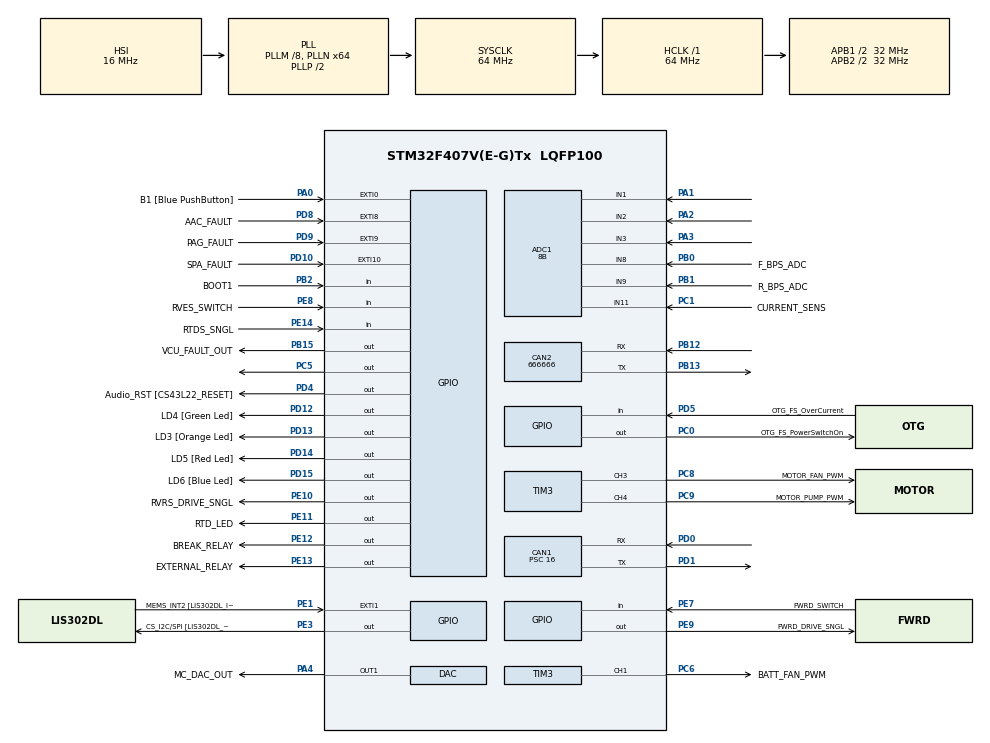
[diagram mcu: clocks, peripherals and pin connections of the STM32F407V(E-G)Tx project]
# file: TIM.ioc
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ADC1.Channel-3\#ChannelRegularConversion=ADC_CHANNEL_1
ADC1.Channel-5\#ChannelRegularConversion=ADC_CHANNEL_2
ADC1.ClockPrescaler=ADC_CLOCK_SYNC_PCLK_DIV2
ADC1.ContinuousConvMode=DISABLE
ADC1.DMAContinuousRequests=ENABLE
ADC1.EOCSelection=ADC_EOC_SEQ_CONV
ADC1.ExternalTrigConv=ADC_EXTERNALTRIGCONV_T2_TRGO
ADC1.NbrOfConversion=2
ADC1.NbrOfConversionFlag=1
ADC1.Rank-3\#ChannelRegularConversion=1
ADC1.Rank-5\#ChannelRegularConversion=2
ADC1.Resolution=ADC_RESOLUTION_8B
ADC1.SamplingTime-3\#ChannelRegularConversion=ADC_SAMPLETIME_3CYCLES
ADC1.SamplingTime-5\#ChannelRegularConversion=ADC_SAMPLETIME_3CYCLES
ADC1.master=1
CAN1.BS1=CAN_BS1_2TQ
CAN1.CalculateBaudRate=500000
CAN1.CalculateTimeBit=2000
CAN1.CalculateTimeQuantum=500.0
CAN1.Prescaler=16
CAN2.CalculateBaudRate=666666
CAN2.CalculateTimeBit=1500
CAN2.CalculateTimeQuantum=500.0
Dma.ADC1.0.Direction=DMA_PERIPH_TO_MEMORY
Dma.ADC1.0.FIFOMode=DMA_FIFOMODE_DISABLE
Dma.ADC1.0.Instance=DMA2_Stream0
Dma.ADC1.0.MemDataAlignment=DMA_MDATAALIGN_HALFWORD
Dma.ADC1.0.MemInc=DMA_MINC_ENABLE
Dma.ADC1.0.Mode=DMA_CIRCULAR
Dma.ADC1.0.PeriphDataAlignment=DMA_PDATAALIGN_HALFWORD
Dma.ADC1.0.PeriphInc=DMA_PINC_DISABLE
Dma.ADC1.0.Priority=DMA_PRIORITY_LOW
Dma.Request0=ADC1
Mcu.Family=STM32F4
Mcu.Name=STM32F407V(E-G)Tx
Mcu.Package=LQFP100
NVIC.ADC_IRQn=true\:0\:0\:false\:false\:true\:true\:true\:true
NVIC.DMA2_Stream0_IRQn=true\:0\:0\:false\:false\:true\:false\:true\:true
NVIC.EXTI0_IRQn=true\:0\:0\:false\:false\:true\:true\:true\:true
NVIC.EXTI15_10_IRQn=true\:0\:0\:false\:false\:true\:true\:true\:true
NVIC.EXTI9_5_IRQn=true\:0\:0\:false\:false\:true\:true\:true\:true
NVIC.PriorityGroup=NVIC_PRIORITYGROUP_0
PA0-WKUP.GPIO_Label=B1 [Blue PushButton]
PA0-WKUP.GPIO_ModeDefaultEXTI=GPIO_MODE_IT_RISING
PA0-WKUP.GPIO_PuPd=GPIO_NOPULL
PA0-WKUP.Signal=GPXTI0
PA1.Signal=ADCx_IN1
PA10.GPIO_Label=OTG_FS_ID
PA10.GPIO_Mode=GPIO_MODE_AF_PP
PA10.GPIO_PuPd=GPIO_NOPULL
PA10.GPIO_Speed=GPIO_SPEED_FREQ_LOW
PA10.Signal=USB_OTG_FS_ID
PA11.GPIO_Label=OTG_FS_DM
PA11.GPIO_Mode=GPIO_MODE_AF_PP
PA11.GPIO_PuPd=GPIO_NOPULL
PA11.GPIO_Speed=GPIO_SPEED_FREQ_LOW
PA11.Signal=USB_OTG_FS_DM
PA12.GPIO_Label=OTG_FS_DP
PA12.GPIO_Mode=GPIO_MODE_AF_PP
PA12.GPIO_PuPd=GPIO_NOPULL
PA12.GPIO_Speed=GPIO_SPEED_FREQ_LOW
PA12.Signal=USB_OTG_FS_DP
PA13.GPIO_Label=SWDIO
PA13.Signal=SYS_JTMS-SWDIO
PA14.GPIO_Label=SWCLK
PA14.Signal=SYS_JTCK-SWCLK
PA2.Signal=ADCx_IN2
PA3.Signal=ADCx_IN3
PA4.GPIO_Label=MC_DAC_OUT
PA4.Signal=COMP_DAC1_group
PA5.GPIO_Label=SPI1_SCK [LIS302DL_SCL/SPC]
PA5.GPIO_Mode=GPIO_MODE_AF_PP
PA5.GPIO_PuPd=GPIO_NOPULL
PA5.GPIO_Speed=GPIO_SPEED_FREQ_LOW
PA5.Signal=SPI1_SCK
PA6.GPIO_Label=SPI1_MISO [LIS302DL_SDO]
PA6.GPIO_Mode=GPIO_MODE_AF_PP
PA6.GPIO_PuPd=GPIO_NOPULL
PA6.GPIO_Speed=GPIO_SPEED_FREQ_LOW
PA6.Signal=SPI1_MISO
PA7.GPIO_Label=SPI1_MOSI [LIS302DL_SDA/SDI/SDO]
PA7.GPIO_Mode=GPIO_MODE_AF_PP
PA7.GPIO_PuPd=GPIO_NOPULL
PA7.GPIO_Speed=GPIO_SPEED_FREQ_LOW
PA7.Signal=SPI1_MOSI
PA9.GPIO_Label=VBUS_FS
PA9.GPIO_Mode=GPIO_MODE_INPUT
PA9.GPIO_PuPd=GPIO_NOPULL
PA9.Signal=USB_OTG_FS_VBUS
PB0.GPIO_Label=F_BPS_ADC
PB0.Signal=ADCx_IN8
PB1.GPIO_Label=R_BPS_ADC
PB1.Signal=ADCx_IN9
PB10.GPIO_Label=CLK_IN [MP45DT02_CLK]
PB10.GPIO_Mode=GPIO_MODE_AF_PP
PB10.GPIO_PuPd=GPIO_NOPULL
PB10.GPIO_Speed=GPIO_SPEED_FREQ_LOW
PB10.Signal=I2S2_CK
PB12.Mode=CAN_Activate
PB12.Signal=CAN2_RX
PB13.Mode=CAN_Activate
PB13.Signal=CAN2_TX
PB15.GPIO_Label=VCU_FAULT_OUT
PB15.Signal=GPIO_Output
PB2.GPIO_Label=BOOT1
PB2.GPIO_Mode=GPIO_MODE_INPUT
PB2.GPIO_PuPd=GPIO_NOPULL
PB2.Signal=GPIO_Input
PB3.GPIO_Label=SWO
PB3.Signal=SYS_JTDO-SWO
PB6.GPIO_Label=Audio_SCL [CS43L22_SCL]
PB6.GPIO_Mode=GPIO_MODE_AF_OD
PB6.GPIO_Pu=GPIO_PULLUP
PB6.GPIO_PuPd=GPIO_NOPULL
PB6.GPIO_Speed=GPIO_SPEED_FREQ_LOW
PB6.Signal=I2C1_SCL
PB9.GPIO_Label=Audio_SDA [CS43L22_SDA]
PB9.GPIO_Mode=GPIO_MODE_AF_OD
PB9.GPIO_Pu=GPIO_PULLUP
PB9.GPIO_PuPd=GPIO_NOPULL
PB9.GPIO_Speed=GPIO_SPEED_FREQ_LOW
PB9.Signal=I2C1_SDA
PC0.GPIO_Label=OTG_FS_PowerSwitchOn
PC0.GPIO_PuPd=GPIO_NOPULL
PC0.GPIO_Speed=GPIO_SPEED_FREQ_LOW
PC0.PinState=GPIO_PIN_SET
PC0.Signal=GPIO_Output
PC1.GPIO_Label=CURRENT_SENS
PC1.Signal=ADCx_IN11
PC10.GPIO_Label=I2S3_SCK [CS43L22_SCLK]
PC10.GPIO_Mode=GPIO_MODE_AF_PP
PC10.GPIO_PuPd=GPIO_NOPULL
PC10.GPIO_Speed=GPIO_SPEED_FREQ_LOW
PC10.Signal=I2S3_CK
PC12.GPIO_Label=I2S3_SD [CS43L22_SDIN]
PC12.GPIO_Mode=GPIO_MODE_AF_PP
PC12.GPIO_PuPd=GPIO_NOPULL
PC12.GPIO_Speed=GPIO_SPEED_FREQ_LOW
PC12.Signal=I2S3_SD
PC14-OSC32_IN.GPIO_Label=PC14-OSC32_IN
PC14-OSC32_IN.Signal=RCC_OSC32_IN
PC15-OSC32_OUT.GPIO_Label=PC15-OSC32_OUT
PC15-OSC32_OUT.Signal=RCC_OSC32_OUT
PC3.GPIO_Label=PDM_OUT [MP45DT02_DOUT]
PC3.GPIO_Mode=GPIO_MODE_AF_PP
PC3.GPIO_PuPd=GPIO_NOPULL
PC3.GPIO_Speed=GPIO_SPEED_FREQ_LOW
PC3.Signal=I2S2_SD
PC5.Signal=GPIO_Output
PC6.GPIO_Label=BATT_FAN_PWM
PC6.Signal=S_TIM3_CH1
PC7.GPIO_Label=I2S3_MCK [CS43L22_MCLK]
PC7.GPIO_Mode=GPIO_MODE_AF_PP
PC7.GPIO_PuPd=GPIO_NOPULL
PC7.GPIO_Speed=GPIO_SPEED_FREQ_LOW
PC7.Signal=I2S3_MCK
PC8.GPIO_Label=MOTOR_FAN_PWM
PC8.Signal=S_TIM3_CH3
PC9.GPIO_Label=MOTOR_PUMP_PWM
PC9.Signal=S_TIM3_CH4
PD0.Mode=CAN_Activate
PD0.Signal=CAN1_RX
PD1.Mode=CAN_Activate
PD1.Signal=CAN1_TX
PD10.GPIO_Label=SPA_FAULT
PD10.GPIO_PuPd=GPIO_NOPULL
PD10.Signal=GPXTI10
PD12.GPIO_Label=LD4 [Green Led]
PD12.GPIO_PuPd=GPIO_NOPULL
PD12.GPIO_Speed=GPIO_SPEED_FREQ_LOW
PD12.Signal=GPIO_Output
PD13.GPIO_Label=LD3 [Orange Led]
PD13.GPIO_PuPd=GPIO_NOPULL
PD13.GPIO_Speed=GPIO_SPEED_FREQ_LOW
PD13.Signal=GPIO_Output
PD14.GPIO_Label=LD5 [Red Led]
PD14.GPIO_PuPd=GPIO_NOPULL
PD14.GPIO_Speed=GPIO_SPEED_FREQ_LOW
PD14.Signal=GPIO_Output
PD15.GPIO_Label=LD6 [Blue Led]
PD15.GPIO_PuPd=GPIO_NOPULL
PD15.GPIO_Speed=GPIO_SPEED_FREQ_LOW
PD15.Signal=GPIO_Output
PD4.GPIO_Label=Audio_RST [CS43L22_RESET]
PD4.GPIO_PuPd=GPIO_NOPULL
PD4.GPIO_Speed=GPIO_SPEED_FREQ_LOW
PD4.Signal=GPIO_Output
PD5.GPIO_Label=OTG_FS_OverCurrent
PD5.GPIO_Mode=GPIO_MODE_INPUT
PD5.GPIO_PuPd=GPIO_NOPULL
PD5.Signal=GPIO_Input
PD8.GPIO_Label=AAC_FAULT
PD8.GPIO_PuPd=GPIO_NOPULL
PD8.Signal=GPXTI8
PD9.GPIO_Label=PAG_FAULT
PD9.GPIO_PuPd=GPIO_NOPULL
PD9.Signal=GPXTI9
PE1.GPIO_Label=MEMS_INT2 [LIS302DL_INT2]
PE1.GPIO_ModeDefaultEXTI=GPIO_MODE_EVT_RISING
PE1.GPIO_PuPd=GPIO_NOPULL
PE1.Signal=GPXTI1
PE10.GPIO_Label=RVRS_DRIVE_SNGL
PE10.Signal=GPIO_Output
PE11.GPIO_Label=RTD_LED
PE11.Signal=GPIO_Output
PE12.GPIO_Label=BREAK_RELAY
PE12.Signal=GPIO_Output
PE13.GPIO_Label=EXTERNAL_RELAY
PE13.Signal=GPIO_Output
PE14.GPIO_Label=RTDS_SNGL
PE14.GPIO_PuPd=GPIO_PULLDOWN
PE14.Signal=GPIO_Input
PE3.GPIO_Label=CS_I2C/SPI [LIS302DL_CS_I2C/SPI]
PE3.GPIO_PuPd=GPIO_NOPULL
PE3.GPIO_Speed=GPIO_SPEED_FREQ_LOW
PE3.Signal=GPIO_Output
PE7.GPIO_Label=FWRD_SWITCH
PE7.Signal=GPIO_Input
PE8.GPIO_Label=RVES_SWITCH
PE8.Signal=GPIO_Input
PE9.GPIO_Label=FWRD_DRIVE_SNGL
PE9.GPIO_ModeDefaultOutputPP=GPIO_MODE_OUTPUT_PP
PE9.GPIO_PuPd=GPIO_NOPULL
PE9.Signal=GPIO_Output
PH0-OSC_IN.GPIO_Label=PH0-OSC_IN
PH0-OSC_IN.Signal=RCC_OSC_IN
PH1-OSC_OUT.GPIO_Label=PH1-OSC_OUT
PH1-OSC_OUT.Signal=RCC_OSC_OUT
ProjectManager.HeapSize=0x200
ProjectManager.StackSize=0x400
ProjectManager.TargetToolchain=STM32CubeIDE
RCC.48MHZClocksFreq_Value=18285714.285714287
RCC.AHBFreq_Value=64000000
RCC.APB1CLKDivider=RCC_HCLK_DIV2
RCC.APB1Freq_Value=32000000
RCC.APB1TimFreq_Value=64000000
RCC.APB2CLKDivider=RCC_HCLK_DIV2
RCC.APB2Freq_Value=32000000
RCC.APB2TimFreq_Value=64000000
RCC.CortexFreq_Value=64000000
RCC.HCLKFreq_Value=64000000
RCC.HSE_VALUE=8000000
RCC.HSI_VALUE=16000000
RCC.LSE_VALUE=32768
RCC.PLLM=8
RCC.PLLN=64
RCC.PLLQ=7
RCC.SYSCLKFreq_VALUE=64000000
RCC.SYSCLKSource=RCC_SYSCLKSOURCE_PLLCLK
RCC.VCOOutputFreq_Value=128000000
SH.ADCx_IN1.0=ADC1_IN1,IN1
SH.ADCx_IN11.0=ADC1_IN11,IN11
SH.ADCx_IN2.0=ADC1_IN2,IN2
SH.ADCx_IN3.0=ADC1_IN3,IN3
SH.ADCx_IN8.0=ADC1_IN8,IN8
SH.ADCx_IN9.0=ADC1_IN9,IN9
SH.COMP_DAC1_group.0=DAC_OUT1,DAC_OUT1
SH.S_TIM3_CH1.0=TIM3_CH1,PWM Generation1 CH1
SH.S_TIM3_CH3.0=TIM3_CH3,PWM Generation3 CH3
SH.S_TIM3_CH4.0=TIM3_CH4,PWM Generation4 CH4
TIM1.Period=0xffff-1
TIM1.Prescaler=64-1
TIM2.Channel-PWM\ Generation1\ No\ Output=TIM_CHANNEL_1
TIM2.Period=65536-1
TIM2.TIM_MasterOutputTrigger=TIM_TRGO_UPDATE
TIM3.Channel-PWM\ Generation1\ CH1=TIM_CHANNEL_1
TIM3.Channel-PWM\ Generation3\ CH3=TIM_CHANNEL_3
TIM3.Channel-PWM\ Generation4\ CH4=TIM_CHANNEL_4
VP_TIM1_VS_ClockSourceINT.Mode=Internal
VP_TIM2_VS_no_output1.Mode=PWM Generation1 No Output
VP_TIM6_VS_ClockSourceINT.Mode=Enable_Timer
VP_TIM8_VS_ClockSourceINT.Mode=Internal
board=STM32F407G-DISC1

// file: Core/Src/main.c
/* USER CODE BEGIN Header */
/**
  ******************************************************************************
  * @file           : main.c
  * @brief          : Main program body
  ******************************************************************************
  * @attention
  *
  * Copyright (c) 2023 STMicroelectronics.
  * All rights reserved.
  *
  * This software is licensed under terms that can be found in the LICENSE file
  * in the root directory of this software component.
  * If no LICENSE file comes with this software, it is provided AS-IS.
  *
  ******************************************************************************
  */
/* USER CODE END Header */
#include "main.h"

/* USER CODE BEGIN Includes */
#include "TIM.h"
#include "DRIVER_IO.h"
#include "app_main.h"
/* USER CODE END Includes */

ADC_HandleTypeDef hadc1;
DMA_HandleTypeDef hdma_adc1;

CAN_HandleTypeDef hcan1;
CAN_HandleTypeDef hcan2;

DAC_HandleTypeDef hdac;

TIM_HandleTypeDef htim1;
TIM_HandleTypeDef htim2;
TIM_HandleTypeDef htim3;
TIM_HandleTypeDef htim6;
TIM_HandleTypeDef htim8;

void SystemClock_Config(void);
static void MX_GPIO_Init(void);
static void MX_DMA_Init(void);
static void MX_TIM1_Init(void);
static void MX_CAN1_Init(void);
static void MX_ADC1_Init(void);
static void MX_DAC_Init(void);
static void MX_TIM6_Init(void);
static void MX_TIM2_Init(void);
static void MX_TIM8_Init(void);
static void MX_CAN2_Init(void);
static void MX_TIM3_Init(void);

int main(void)
{

  /* MCU Configuration--------------------------------------------------------*/

  /* Reset of all peripherals, Initializes the Flash interface and the Systick. */
  HAL_Init();

  /* Configure the system clock */
  SystemClock_Config();

  /* Initialize all configured peripherals */
  MX_GPIO_Init();
  MX_DMA_Init();
  MX_TIM1_Init();
  MX_CAN1_Init();
  MX_ADC1_Init();
  MX_DAC_Init();
  MX_TIM6_Init();
  MX_TIM2_Init();
  MX_TIM8_Init();
  MX_CAN2_Init();
  MX_TIM3_Init();
  /* USER CODE BEGIN 2 */
  AppConfig();
  AppMain();
  /* USER CODE END 2 */

  /* Infinite loop */
  /* USER CODE BEGIN WHILE */
  while (1)		// We don't use this, instead we use the loop inside AppMain()
  {
    /* USER CODE END WHILE */

  }
}

void SystemClock_Config(void)
{
  RCC_OscInitTypeDef RCC_OscInitStruct = {0};
  RCC_ClkInitTypeDef RCC_ClkInitStruct = {0};

  /** Configure the main internal regulator output voltage
  */
  __HAL_RCC_PWR_CLK_ENABLE();
  __HAL_PWR_VOLTAGESCALING_CONFIG(PWR_REGULATOR_VOLTAGE_SCALE1);

  /** Initializes the RCC Oscillators according to the specified parameters
  * in the RCC_OscInitTypeDef structure.
  */
  RCC_OscInitStruct.OscillatorType = RCC_OSCILLATORTYPE_HSI;
  RCC_OscInitStruct.HSIState = RCC_HSI_ON;
  RCC_OscInitStruct.HSICalibrationValue = RCC_HSICALIBRATION_DEFAULT;
  RCC_OscInitStruct.PLL.PLLState = RCC_PLL_ON;
  RCC_OscInitStruct.PLL.PLLSource = RCC_PLLSOURCE_HSI;
  RCC_OscInitStruct.PLL.PLLM = 8;
  RCC_OscInitStruct.PLL.PLLN = 64;
  RCC_OscInitStruct.PLL.PLLP = RCC_PLLP_DIV2;
  RCC_OscInitStruct.PLL.PLLQ = 7;
  if (HAL_RCC_OscConfig(&RCC_OscInitStruct) != HAL_OK)
  {
    Error_Handler();
  }

  /** Initializes the CPU, AHB and APB buses clocks
  */
  RCC_ClkInitStruct.ClockType = RCC_CLOCKTYPE_HCLK|RCC_CLOCKTYPE_SYSCLK
                              |RCC_CLOCKTYPE_PCLK1|RCC_CLOCKTYPE_PCLK2;
  RCC_ClkInitStruct.SYSCLKSource = RCC_SYSCLKSOURCE_PLLCLK;
  RCC_ClkInitStruct.AHBCLKDivider = RCC_SYSCLK_DIV1;
  RCC_ClkInitStruct.APB1CLKDivider = RCC_HCLK_DIV2;
  RCC_ClkInitStruct.APB2CLKDivider = RCC_HCLK_DIV2;

  if (HAL_RCC_ClockConfig(&RCC_ClkInitStruct, FLASH_LATENCY_2) != HAL_OK)
  {
    Error_Handler();
  }
}

static void MX_ADC1_Init(void)
{

  ADC_ChannelConfTypeDef sConfig = {0};

  /** Configure the global features of the ADC (Clock, Resolution, Data Alignment and number of conversion)
  */
  hadc1.Instance = ADC1;
  hadc1.Init.ClockPrescaler = ADC_CLOCK_SYNC_PCLK_DIV2;
  hadc1.Init.Resolution = ADC_RESOLUTION_8B;
  hadc1.Init.ScanConvMode = ENABLE;
  hadc1.Init.ContinuousConvMode = DISABLE;
  hadc1.Init.DiscontinuousConvMode = DISABLE;
  hadc1.Init.ExternalTrigConvEdge = ADC_EXTERNALTRIGCONVEDGE_RISING;
  hadc1.Init.ExternalTrigConv = ADC_EXTERNALTRIGCONV_T2_TRGO;
  hadc1.Init.DataAlign = ADC_DATAALIGN_RIGHT;
  hadc1.Init.NbrOfConversion = 2;
  hadc1.Init.DMAContinuousRequests = ENABLE;
  hadc1.Init.EOCSelection = ADC_EOC_SEQ_CONV;
  if (HAL_ADC_Init(&hadc1) != HAL_OK)
  {
    Error_Handler();
  }

  /** Configure for the selected ADC regular channel its corresponding rank in the sequencer and its sample time.
  */
  sConfig.Channel = ADC_CHANNEL_1;
  sConfig.Rank = 1;
  sConfig.SamplingTime = ADC_SAMPLETIME_3CYCLES;
  if (HAL_ADC_ConfigChannel(&hadc1, &sConfig) != HAL_OK)
  {
    Error_Handler();
  }

  /** Configure for the selected ADC regular channel its corresponding rank in the sequencer and its sample time.
  */
  sConfig.Channel = ADC_CHANNEL_2;
  sConfig.Rank = 2;
  if (HAL_ADC_ConfigChannel(&hadc1, &sConfig) != HAL_OK)
  {
    Error_Handler();
  }

}

static void MX_CAN1_Init(void)
{

  hcan1.Instance = CAN1;
  hcan1.Init.Prescaler = 16;
  hcan1.Init.Mode = CAN_MODE_NORMAL;
  hcan1.Init.SyncJumpWidth = CAN_SJW_1TQ;
  hcan1.Init.TimeSeg1 = CAN_BS1_2TQ;
  hcan1.Init.TimeSeg2 = CAN_BS2_1TQ;
  hcan1.Init.TimeTriggeredMode = DISABLE;
  hcan1.Init.AutoBusOff = DISABLE;
  hcan1.Init.AutoWakeUp = DISABLE;
  hcan1.Init.AutoRetransmission = DISABLE;
  hcan1.Init.ReceiveFifoLocked = DISABLE;
  hcan1.Init.TransmitFifoPriority = DISABLE;
  if (HAL_CAN_Init(&hcan1) != HAL_OK)
  {
    Error_Handler();
  }

}

static void MX_CAN2_Init(void)
{

  hcan2.Instance = CAN2;
  hcan2.Init.Prescaler = 16;
  hcan2.Init.Mode = CAN_MODE_NORMAL;
  hcan2.Init.SyncJumpWidth = CAN_SJW_1TQ;
  hcan2.Init.TimeSeg1 = CAN_BS1_1TQ;
  hcan2.Init.TimeSeg2 = CAN_BS2_1TQ;
  hcan2.Init.TimeTriggeredMode = DISABLE;
  hcan2.Init.AutoBusOff = DISABLE;
  hcan2.Init.AutoWakeUp = DISABLE;
  hcan2.Init.AutoRetransmission = DISABLE;
  hcan2.Init.ReceiveFifoLocked = DISABLE;
  hcan2.Init.TransmitFifoPriority = DISABLE;
  if (HAL_CAN_Init(&hcan2) != HAL_OK)
  {
    Error_Handler();
  }

}

static void MX_DAC_Init(void)
{

  DAC_ChannelConfTypeDef sConfig = {0};

  /** DAC Initialization
  */
  hdac.Instance = DAC;
  if (HAL_DAC_Init(&hdac) != HAL_OK)
  {
    Error_Handler();
  }

  /** DAC channel OUT1 config
  */
  sConfig.DAC_Trigger = DAC_TRIGGER_NONE;
  sConfig.DAC_OutputBuffer = DAC_OUTPUTBUFFER_ENABLE;
  if (HAL_DAC_ConfigChannel(&hdac, &sConfig, DAC_CHANNEL_1) != HAL_OK)
  {
    Error_Handler();
  }

}

static void MX_TIM1_Init(void)
{

  TIM_ClockConfigTypeDef sClockSourceConfig = {0};
  TIM_MasterConfigTypeDef sMasterConfig = {0};

  htim1.Instance = TIM1;
  htim1.Init.Prescaler = 64-1;
  htim1.Init.CounterMode = TIM_COUNTERMODE_UP;
  htim1.Init.Period = 0xffff-1;
  htim1.Init.ClockDivision = TIM_CLOCKDIVISION_DIV1;
  htim1.Init.RepetitionCounter = 0;
  htim1.Init.AutoReloadPreload = TIM_AUTORELOAD_PRELOAD_DISABLE;
  if (HAL_TIM_Base_Init(&htim1) != HAL_OK)
  {
    Error_Handler();
  }
  sClockSourceConfig.ClockSource = TIM_CLOCKSOURCE_INTERNAL;
  if (HAL_TIM_ConfigClockSource(&htim1, &sClockSourceConfig) != HAL_OK)
  {
    Error_Handler();
  }
  sMasterConfig.MasterOutputTrigger = TIM_TRGO_RESET;
  sMasterConfig.MasterSlaveMode = TIM_MASTERSLAVEMODE_DISABLE;
  if (HAL_TIMEx_MasterConfigSynchronization(&htim1, &sMasterConfig) != HAL_OK)
  {
    Error_Handler();
  }

}

static void MX_TIM2_Init(void)
{

  TIM_MasterConfigTypeDef sMasterConfig = {0};
  TIM_OC_InitTypeDef sConfigOC = {0};

  htim2.Instance = TIM2;
  htim2.Init.Prescaler = 0;
  htim2.Init.CounterMode = TIM_COUNTERMODE_UP;
  htim2.Init.Period = 65536-1;
  htim2.Init.ClockDivision = TIM_CLOCKDIVISION_DIV1;
  htim2.Init.AutoReloadPreload = TIM_AUTORELOAD_PRELOAD_DISABLE;
  if (HAL_TIM_PWM_Init(&htim2) != HAL_OK)
  {
    Error_Handler();
  }
  sMasterConfig.MasterOutputTrigger = TIM_TRGO_UPDATE;
  sMasterConfig.MasterSlaveMode = TIM_MASTERSLAVEMODE_DISABLE;
  if (HAL_TIMEx_MasterConfigSynchronization(&htim2, &sMasterConfig) != HAL_OK)
  {
    Error_Handler();
  }
  sConfigOC.OCMode = TIM_OCMODE_PWM1;
  sConfigOC.Pulse = 0;
  sConfigOC.OCPolarity = TIM_OCPOLARITY_HIGH;
  sConfigOC.OCFastMode = TIM_OCFAST_DISABLE;
  if (HAL_TIM_PWM_ConfigChannel(&htim2, &sConfigOC, TIM_CHANNEL_1) != HAL_OK)
  {
    Error_Handler();
  }

}

static void MX_TIM3_Init(void)
{

  TIM_MasterConfigTypeDef sMasterConfig = {0};
  TIM_OC_InitTypeDef sConfigOC = {0};

  htim3.Instance = TIM3;
  htim3.Init.Prescaler = 0;
  htim3.Init.CounterMode = TIM_COUNTERMODE_UP;
  htim3.Init.Period = 65535;
  htim3.Init.ClockDivision = TIM_CLOCKDIVISION_DIV1;
  htim3.Init.AutoReloadPreload = TIM_AUTORELOAD_PRELOAD_DISABLE;
  if (HAL_TIM_PWM_Init(&htim3) != HAL_OK)
  {
    Error_Handler();
  }
  sMasterConfig.MasterOutputTrigger = TIM_TRGO_RESET;
  sMasterConfig.MasterSlaveMode = TIM_MASTERSLAVEMODE_DISABLE;
  if (HAL_TIMEx_MasterConfigSynchronization(&htim3, &sMasterConfig) != HAL_OK)
  {
    Error_Handler();
  }
  sConfigOC.OCMode = TIM_OCMODE_PWM1;
  sConfigOC.Pulse = 0;
  sConfigOC.OCPolarity = TIM_OCPOLARITY_HIGH;
  sConfigOC.OCFastMode = TIM_OCFAST_DISABLE;
  if (HAL_TIM_PWM_ConfigChannel(&htim3, &sConfigOC, TIM_CHANNEL_1) != HAL_OK)
  {
    Error_Handler();
  }
  if (HAL_TIM_PWM_ConfigChannel(&htim3, &sConfigOC, TIM_CHANNEL_3) != HAL_OK)
  {
    Error_Handler();
  }
  if (HAL_TIM_PWM_ConfigChannel(&htim3, &sConfigOC, TIM_CHANNEL_4) != HAL_OK)
  {
    Error_Handler();
  }
  HAL_TIM_MspPostInit(&htim3);

}

static void MX_TIM6_Init(void)
{

  TIM_MasterConfigTypeDef sMasterConfig = {0};

  htim6.Instance = TIM6;
  htim6.Init.Prescaler = 0;
  htim6.Init.CounterMode = TIM_COUNTERMODE_UP;
  htim6.Init.Period = 65535;
  htim6.Init.AutoReloadPreload = TIM_AUTORELOAD_PRELOAD_DISABLE;
  if (HAL_TIM_Base_Init(&htim6) != HAL_OK)
  {
    Error_Handler();
  }
  sMasterConfig.MasterOutputTrigger = TIM_TRGO_RESET;
  sMasterConfig.MasterSlaveMode = TIM_MASTERSLAVEMODE_DISABLE;
  if (HAL_TIMEx_MasterConfigSynchronization(&htim6, &sMasterConfig) != HAL_OK)
  {
    Error_Handler();
  }

}

static void MX_TIM8_Init(void)
{

  TIM_ClockConfigTypeDef sClockSourceConfig = {0};
  TIM_MasterConfigTypeDef sMasterConfig = {0};

  htim8.Instance = TIM8;
  htim8.Init.Prescaler = 0;
  htim8.Init.CounterMode = TIM_COUNTERMODE_UP;
  htim8.Init.Period = 65535;
  htim8.Init.ClockDivision = TIM_CLOCKDIVISION_DIV1;
  htim8.Init.RepetitionCounter = 0;
  htim8.Init.AutoReloadPreload = TIM_AUTORELOAD_PRELOAD_DISABLE;
  if (HAL_TIM_Base_Init(&htim8) != HAL_OK)
  {
    Error_Handler();
  }
  sClockSourceConfig.ClockSource = TIM_CLOCKSOURCE_INTERNAL;
  if (HAL_TIM_ConfigClockSource(&htim8, &sClockSourceConfig) != HAL_OK)
  {
    Error_Handler();
  }
  sMasterConfig.MasterOutputTrigger = TIM_TRGO_RESET;
  sMasterConfig.MasterSlaveMode = TIM_MASTERSLAVEMODE_DISABLE;
  if (HAL_TIMEx_MasterConfigSynchronization(&htim8, &sMasterConfig) != HAL_OK)
  {
    Error_Handler();
  }

}

static void MX_DMA_Init(void)
{

  /* DMA controller clock enable */
  __HAL_RCC_DMA2_CLK_ENABLE();

  /* DMA interrupt init */
  /* DMA2_Stream0_IRQn interrupt configuration */
  HAL_NVIC_SetPriority(DMA2_Stream0_IRQn, 0, 0);
  HAL_NVIC_EnableIRQ(DMA2_Stream0_IRQn);

}

static void MX_GPIO_Init(void)
{
  GPIO_InitTypeDef GPIO_InitStruct = {0};

  /* GPIO Ports Clock Enable */
  __HAL_RCC_GPIOE_CLK_ENABLE();
  __HAL_RCC_GPIOC_CLK_ENABLE();
  __HAL_RCC_GPIOH_CLK_ENABLE();
  __HAL_RCC_GPIOA_CLK_ENABLE();
  __HAL_RCC_GPIOB_CLK_ENABLE();
  __HAL_RCC_GPIOD_CLK_ENABLE();

  /*Configure GPIO pin Output Level */
  HAL_GPIO_WritePin(GPIOE, CS_I2C_SPI_Pin|FWRD_DRIVE_SNGL_Pin|RVRS_DRIVE_SNGL_Pin|RTD_LED_Pin
                          |BREAK_RELAY_Pin|EXTERNAL_RELAY_Pin, GPIO_PIN_RESET);

  /*Configure GPIO pin Output Level */
  HAL_GPIO_WritePin(OTG_FS_PowerSwitchOn_GPIO_Port, OTG_FS_PowerSwitchOn_Pin, GPIO_PIN_SET);

  /*Configure GPIO pin Output Level */
  HAL_GPIO_WritePin(GPIOC, GPIO_PIN_5, GPIO_PIN_RESET);

  /*Configure GPIO pin Output Level */
  HAL_GPIO_WritePin(VCU_FAULT_OUT_GPIO_Port, VCU_FAULT_OUT_Pin, GPIO_PIN_RESET);

  /*Configure GPIO pin Output Level */
  HAL_GPIO_WritePin(GPIOD, LD4_Pin|LD3_Pin|LD5_Pin|LD6_Pin
                          |Audio_RST_Pin, GPIO_PIN_RESET);

  /*Configure GPIO pins : CS_I2C_SPI_Pin FWRD_DRIVE_SNGL_Pin RVRS_DRIVE_SNGL_Pin RTD_LED_Pin
                           BREAK_RELAY_Pin EXTERNAL_RELAY_Pin */
  GPIO_InitStruct.Pin = CS_I2C_SPI_Pin|FWRD_DRIVE_SNGL_Pin|RVRS_DRIVE_SNGL_Pin|RTD_LED_Pin
                          |BREAK_RELAY_Pin|EXTERNAL_RELAY_Pin;
  GPIO_InitStruct.Mode = GPIO_MODE_OUTPUT_PP;
  GPIO_InitStruct.Pull = GPIO_NOPULL;
  GPIO_InitStruct.Speed = GPIO_SPEED_FREQ_LOW;
  HAL_GPIO_Init(GPIOE, &GPIO_InitStruct);

  /*Configure GPIO pins : OTG_FS_PowerSwitchOn_Pin PC5 */
  GPIO_InitStruct.Pin = OTG_FS_PowerSwitchOn_Pin|GPIO_PIN_5;
  GPIO_InitStruct.Mode = GPIO_MODE_OUTPUT_PP;
  GPIO_InitStruct.Pull = GPIO_NOPULL;
  GPIO_InitStruct.Speed = GPIO_SPEED_FREQ_LOW;
  HAL_GPIO_Init(GPIOC, &GPIO_InitStruct);

  /*Configure GPIO pin : PDM_OUT_Pin */
  GPIO_InitStruct.Pin = PDM_OUT_Pin;
  GPIO_InitStruct.Mode = GPIO_MODE_AF_PP;
  GPIO_InitStruct.Pull = GPIO_NOPULL;
  GPIO_InitStruct.Speed = GPIO_SPEED_FREQ_LOW;
  GPIO_InitStruct.Alternate = GPIO_AF5_SPI2;
  HAL_GPIO_Init(PDM_OUT_GPIO_Port, &GPIO_InitStruct);

  /*Configure GPIO pin : B1_Pin */
  GPIO_InitStruct.Pin = B1_Pin;
  GPIO_InitStruct.Mode = GPIO_MODE_IT_RISING;
  GPIO_InitStruct.Pull = GPIO_NOPULL;
  HAL_GPIO_Init(B1_GPIO_Port, &GPIO_InitStruct);

  /*Configure GPIO pins : SPI1_SCK_Pin SPI1_MISO_Pin SPI1_MOSI_Pin */
  GPIO_InitStruct.Pin = SPI1_SCK_Pin|SPI1_MISO_Pin|SPI1_MOSI_Pin;
  GPIO_InitStruct.Mode = GPIO_MODE_AF_PP;
  GPIO_InitStruct.Pull = GPIO_NOPULL;
  GPIO_InitStruct.Speed = GPIO_SPEED_FREQ_LOW;
  GPIO_InitStruct.Alternate = GPIO_AF5_SPI1;
  HAL_GPIO_Init(GPIOA, &GPIO_InitStruct);

  /*Configure GPIO pin : BOOT1_Pin */
  GPIO_InitStruct.Pin = BOOT1_Pin;
  GPIO_InitStruct.Mode = GPIO_MODE_INPUT;
  GPIO_InitStruct.Pull = GPIO_NOPULL;
  HAL_GPIO_Init(BOOT1_GPIO_Port, &GPIO_InitStruct);

  /*Configure GPIO pins : FWRD_SWITCH_Pin RVES_SWITCH_Pin */
  GPIO_InitStruct.Pin = FWRD_SWITCH_Pin|RVES_SWITCH_Pin;
  GPIO_InitStruct.Mode = GPIO_MODE_INPUT;
  GPIO_InitStruct.Pull = GPIO_NOPULL;
  HAL_GPIO_Init(GPIOE, &GPIO_InitStruct);

  /*Configure GPIO pin : RTDS_SNGL_Pin */
  GPIO_InitStruct.Pin = RTDS_SNGL_Pin;
  GPIO_InitStruct.Mode = GPIO_MODE_INPUT;
  GPIO_InitStruct.Pull = GPIO_PULLDOWN;
  HAL_GPIO_Init(RTDS_SNGL_GPIO_Port, &GPIO_InitStruct);

  /*Configure GPIO pin : CLK_IN_Pin */
  GPIO_InitStruct.Pin = CLK_IN_Pin;
  GPIO_InitStruct.Mode = GPIO_MODE_AF_PP;
  GPIO_InitStruct.Pull = GPIO_NOPULL;
  GPIO_InitStruct.Speed = GPIO_SPEED_FREQ_LOW;
  GPIO_InitStruct.Alternate = GPIO_AF5_SPI2;
  HAL_GPIO_Init(CLK_IN_GPIO_Port, &GPIO_InitStruct);

  /*Configure GPIO pin : VCU_FAULT_OUT_Pin */
  GPIO_InitStruct.Pin = VCU_FAULT_OUT_Pin;
  GPIO_InitStruct.Mode = GPIO_MODE_OUTPUT_PP;
  GPIO_InitStruct.Pull = GPIO_NOPULL;
  GPIO_InitStruct.Speed = GPIO_SPEED_FREQ_LOW;
  HAL_GPIO_Init(VCU_FAULT_OUT_GPIO_Port, &GPIO_InitStruct);

  /*Configure GPIO pins : AAC_FAULT_Pin PAG_FAULT_Pin SPA_FAULT_Pin */
  GPIO_InitStruct.Pin = AAC_FAULT_Pin|PAG_FAULT_Pin|SPA_FAULT_Pin;
  GPIO_InitStruct.Mode = GPIO_MODE_IT_RISING;
  GPIO_InitStruct.Pull = GPIO_NOPULL;
  HAL_GPIO_Init(GPIOD, &GPIO_InitStruct);

  /*Configure GPIO pins : LD4_Pin LD3_Pin LD5_Pin LD6_Pin
                           Audio_RST_Pin */
  GPIO_InitStruct.Pin = LD4_Pin|LD3_Pin|LD5_Pin|LD6_Pin
                          |Audio_RST_Pin;
  GPIO_InitStruct.Mode = GPIO_MODE_OUTPUT_PP;
  GPIO_InitStruct.Pull = GPIO_NOPULL;
  GPIO_InitStruct.Speed = GPIO_SPEED_FREQ_LOW;
  HAL_GPIO_Init(GPIOD, &GPIO_InitStruct);

  /*Configure GPIO pins : I2S3_MCK_Pin I2S3_SCK_Pin I2S3_SD_Pin */
  GPIO_InitStruct.Pin = I2S3_MCK_Pin|I2S3_SCK_Pin|I2S3_SD_Pin;
  GPIO_InitStruct.Mode = GPIO_MODE_AF_PP;
  GPIO_InitStruct.Pull = GPIO_NOPULL;
  GPIO_InitStruct.Speed = GPIO_SPEED_FREQ_LOW;
  GPIO_InitStruct.Alternate = GPIO_AF6_SPI3;
  HAL_GPIO_Init(GPIOC, &GPIO_InitStruct);

  /*Configure GPIO pin : VBUS_FS_Pin */
  GPIO_InitStruct.Pin = VBUS_FS_Pin;
  GPIO_InitStruct.Mode = GPIO_MODE_INPUT;
  GPIO_InitStruct.Pull = GPIO_NOPULL;
  HAL_GPIO_Init(VBUS_FS_GPIO_Port, &GPIO_InitStruct);

  /*Configure GPIO pins : OTG_FS_ID_Pin OTG_FS_DM_Pin OTG_FS_DP_Pin */
  GPIO_InitStruct.Pin = OTG_FS_ID_Pin|OTG_FS_DM_Pin|OTG_FS_DP_Pin;
  GPIO_InitStruct.Mode = GPIO_MODE_AF_PP;
  GPIO_InitStruct.Pull = GPIO_NOPULL;
  GPIO_InitStruct.Speed = GPIO_SPEED_FREQ_LOW;
  GPIO_InitStruct.Alternate = GPIO_AF10_OTG_FS;
  HAL_GPIO_Init(GPIOA, &GPIO_InitStruct);

  /*Configure GPIO pin : OTG_FS_OverCurrent_Pin */
  GPIO_InitStruct.Pin = OTG_FS_OverCurrent_Pin;
  GPIO_InitStruct.Mode = GPIO_MODE_INPUT;
  GPIO_InitStruct.Pull = GPIO_NOPULL;
  HAL_GPIO_Init(OTG_FS_OverCurrent_GPIO_Port, &GPIO_InitStruct);

  /*Configure GPIO pins : Audio_SCL_Pin Audio_SDA_Pin */
  GPIO_InitStruct.Pin = Audio_SCL_Pin|Audio_SDA_Pin;
  GPIO_InitStruct.Mode = GPIO_MODE_AF_OD;
  GPIO_InitStruct.Pull = GPIO_PULLUP;
  GPIO_InitStruct.Speed = GPIO_SPEED_FREQ_LOW;
  GPIO_InitStruct.Alternate = GPIO_AF4_I2C1;
  HAL_GPIO_Init(GPIOB, &GPIO_InitStruct);

  /*Configure GPIO pin : MEMS_INT2_Pin */
  GPIO_InitStruct.Pin = MEMS_INT2_Pin;
  GPIO_InitStruct.Mode = GPIO_MODE_EVT_RISING;
  GPIO_InitStruct.Pull = GPIO_NOPULL;
  HAL_GPIO_Init(MEMS_INT2_GPIO_Port, &GPIO_InitStruct);

  /* EXTI interrupt init*/
  HAL_NVIC_SetPriority(EXTI0_IRQn, 0, 0);
  HAL_NVIC_EnableIRQ(EXTI0_IRQn);

  HAL_NVIC_SetPriority(EXTI9_5_IRQn, 0, 0);
  HAL_NVIC_EnableIRQ(EXTI9_5_IRQn);

  HAL_NVIC_SetPriority(EXTI15_10_IRQn, 0, 0);
  HAL_NVIC_EnableIRQ(EXTI15_10_IRQn);

}

/* USER CODE BEGIN 4 */

// Called when first half of the buffer is filled

/* USER CODE END 4 */

void Error_Handler(void)
{
  /* USER CODE BEGIN Error_Handler_Debug */
  /* User can add his own implementation to report the HAL error return state */
  __disable_irq();
  while (1)
  {
	  // WE DO NOT WANT TO BE HERE :(
  }
  /* USER CODE END Error_Handler_Debug */
}
